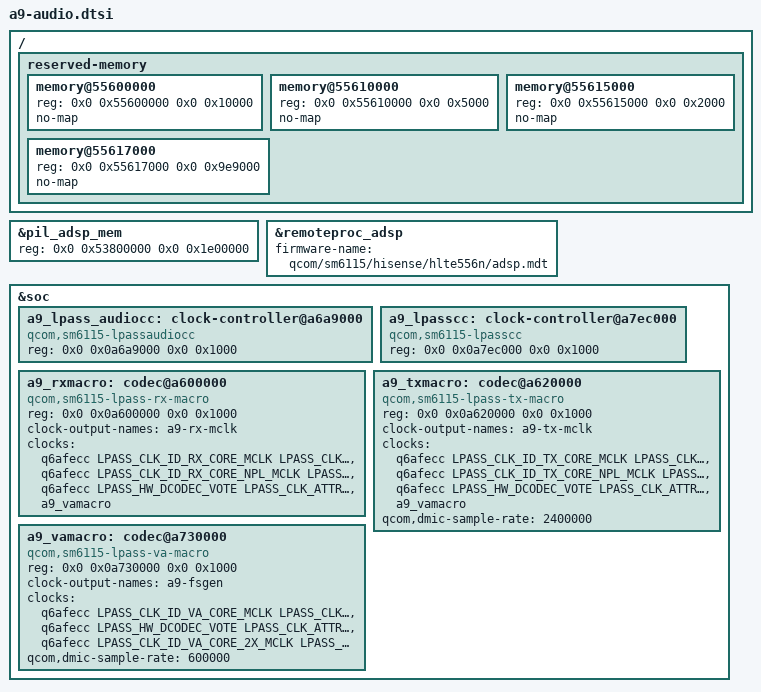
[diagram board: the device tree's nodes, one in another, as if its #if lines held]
// SPDX-License-Identifier: (GPL-2.0-only OR BSD-2-Clause)
/*
 * Hisense A9 audio infrastructure, opt-in only.
 * Stock addresses/clock identities are measured from the golden boot DT.
 * ADSP uses the existing SM6115 APR-v2 graph; do not substitute GPR/APM.
 * No SoundWire controller, WCD937x or PA is instantiated until its unresolved
 * identity, supply and bus timing details are established.
 *
 * RX/TX/VA MMIO lengths below cover the upstream driver's register windows;
 * downstream DT records address-only (length zero) and cannot supply lengths.
 * Keep macros disabled by default. A9_AUDIO_ENABLE_MACROS is a separate,
 * experimental probe gate, not a claim that any audio endpoint works.
 */
#include <dt-bindings/clock/qcom,sm6115-lpasscc.h>
#include <dt-bindings/sound/qcom,q6dsp-lpass-ports.h>

&pil_adsp_mem {
	/* Stock ADSP carveout ends at 0x55600000. */
	reg = <0x0 0x53800000 0x0 0x1e00000>;
};

/ {
	reserved-memory {
		/*
		 * Review 33 F1: shrinking ADSP to the stock size must not hand
		 * 0x55600000-0x56000000 to Linux. Stock reserves IPA fw/GSI and
		 * the GPU zap region there (stock base DTB ipa_fw_region@55600000
		 * 0x10000, ipa_gsi_region@55610000 0x5000, zap 0x55615000 0x2000).
		 * The remainder of upstream's ADSP range stays no-map as a tail, so
		 * nothing the default Android DT reserves is released. Node names
		 * and regs are identical to the gpu branch's
		 * sm6115-hisense-hlte556n-android-gpu.dts, so a combined DT merges
		 * them instead of overlapping. Audited by dt-reserved-audit.py.
		 */
		memory@55600000 {
			reg = <0x0 0x55600000 0x0 0x10000>;
			no-map;
		};

		memory@55610000 {
			reg = <0x0 0x55610000 0x0 0x5000>;
			no-map;
		};

		memory@55615000 {
			reg = <0x0 0x55615000 0x0 0x2000>;
			no-map;
		};

		memory@55617000 {
			reg = <0x0 0x55617000 0x0 0x9e9000>;
			no-map;
		};
	};
};

/*
 * Review 33 F2: the ADSP has its own explicit switch. qcom_q6v5_pas auto-boots
 * every enabled PAS node when the module loads, and the Wi-Fi build loads that
 * module for MPSS, so ADSP must stay disabled unless this audio-specific
 * opt-in (build-kernel.py --enable-adsp) is given.
 */
&remoteproc_adsp {
	firmware-name = "qcom/sm6115/hisense/hlte556n/adsp.mdt";
#ifdef A9_AUDIO_ENABLE_ADSP
	status = "okay";
#else
	status = "disabled";
#endif
};

&soc {
	a9_lpass_audiocc: clock-controller@a6a9000 {
		compatible = "qcom,sm6115-lpassaudiocc";
		reg = <0x0 0x0a6a9000 0x0 0x1000>;
		#reset-cells = <1>;
	};

	a9_lpasscc: clock-controller@a7ec000 {
		compatible = "qcom,sm6115-lpasscc";
		reg = <0x0 0x0a7ec000 0x0 0x1000>;
		#reset-cells = <1>;
	};

	a9_rxmacro: codec@a600000 {
		compatible = "qcom,sm6115-lpass-rx-macro";
		reg = <0x0 0x0a600000 0x0 0x1000>;
		#sound-dai-cells = <1>;
		#clock-cells = <0>;
		clock-output-names = "a9-rx-mclk";
		clocks = <&q6afecc LPASS_CLK_ID_RX_CORE_MCLK LPASS_CLK_ATTRIBUTE_COUPLE_NO>,
			 <&q6afecc LPASS_CLK_ID_RX_CORE_NPL_MCLK LPASS_CLK_ATTRIBUTE_COUPLE_NO>,
			 <&q6afecc LPASS_HW_DCODEC_VOTE LPASS_CLK_ATTRIBUTE_COUPLE_NO>,
			 <&a9_vamacro>;
		clock-names = "mclk", "npl", "dcodec", "fsgen";
#ifdef A9_AUDIO_ENABLE_MACROS
		status = "okay";
#else
		status = "disabled";
#endif
	};

	a9_txmacro: codec@a620000 {
		compatible = "qcom,sm6115-lpass-tx-macro";
		reg = <0x0 0x0a620000 0x0 0x1000>;
		#sound-dai-cells = <1>;
		#clock-cells = <0>;
		clock-output-names = "a9-tx-mclk";
		clocks = <&q6afecc LPASS_CLK_ID_TX_CORE_MCLK LPASS_CLK_ATTRIBUTE_COUPLE_NO>,
			 <&q6afecc LPASS_CLK_ID_TX_CORE_NPL_MCLK LPASS_CLK_ATTRIBUTE_COUPLE_NO>,
			 <&q6afecc LPASS_HW_DCODEC_VOTE LPASS_CLK_ATTRIBUTE_COUPLE_NO>,
			 <&a9_vamacro>;
		clock-names = "mclk", "npl", "dcodec", "fsgen";
		qcom,dmic-sample-rate = <2400000>;
#ifdef A9_AUDIO_ENABLE_MACROS
		status = "okay";
#else
		status = "disabled";
#endif
	};

	a9_vamacro: codec@a730000 {
		compatible = "qcom,sm6115-lpass-va-macro";
		reg = <0x0 0x0a730000 0x0 0x1000>;
		#sound-dai-cells = <1>;
		#clock-cells = <0>;
		clock-output-names = "a9-fsgen";
		clocks = <&q6afecc LPASS_CLK_ID_VA_CORE_MCLK LPASS_CLK_ATTRIBUTE_COUPLE_NO>,
			 <&q6afecc LPASS_HW_DCODEC_VOTE LPASS_CLK_ATTRIBUTE_COUPLE_NO>,
			 <&q6afecc LPASS_CLK_ID_VA_CORE_2X_MCLK LPASS_CLK_ATTRIBUTE_COUPLE_NO>;
		clock-names = "mclk", "dcodec", "npl";
		qcom,dmic-sample-rate = <600000>;
#ifdef A9_AUDIO_ENABLE_MACROS
		status = "okay";
#else
		status = "disabled";
#endif
	};
};
